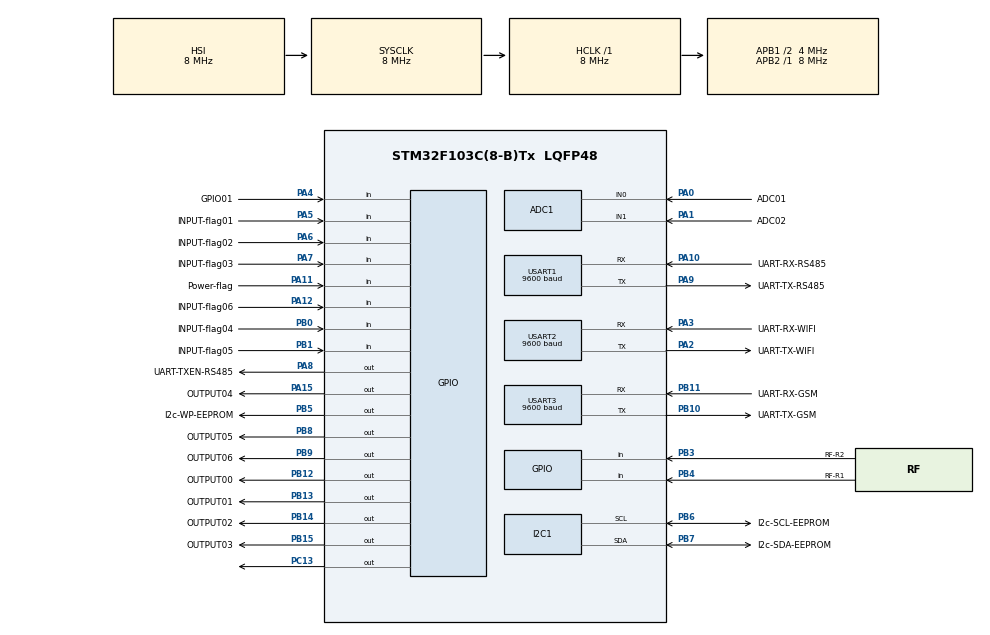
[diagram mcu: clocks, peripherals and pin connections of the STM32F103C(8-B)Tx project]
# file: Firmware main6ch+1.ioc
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ADC1.Channel-0\#ChannelRegularConversion=ADC_CHANNEL_0
ADC1.NbrOfConversionFlag=1
ADC1.Rank-0\#ChannelRegularConversion=1
ADC1.SamplingTime-0\#ChannelRegularConversion=ADC_SAMPLETIME_1CYCLE_5
ADC1.master=1
Mcu.Family=STM32F1
Mcu.Name=STM32F103C(8-B)Tx
Mcu.Package=LQFP48
NVIC.PriorityGroup=NVIC_PRIORITYGROUP_4
PA0-WKUP.GPIO_Label=ADC01
PA0-WKUP.Signal=ADCx_IN0
PA1.GPIO_Label=ADC02
PA1.Signal=ADCx_IN1
PA10.GPIO_Label=UART-RX-RS485
PA10.Mode=Asynchronous
PA10.Signal=USART1_RX
PA11.GPIO_Label=Power-flag
PA11.Signal=GPIO_Input
PA12.GPIO_Label=INPUT-flag06
PA12.Signal=GPIO_Input
PA13.Mode=Serial_Wire
PA13.Signal=SYS_JTMS-SWDIO
PA14.Mode=Serial_Wire
PA14.Signal=SYS_JTCK-SWCLK
PA15.GPIO_Label=OUTPUT04
PA15.Signal=GPIO_Output
PA2.GPIO_Label=UART-TX-WIFI
PA2.Mode=Asynchronous
PA2.Signal=USART2_TX
PA3.GPIO_Label=UART-RX-WIFI
PA3.Mode=Asynchronous
PA3.Signal=USART2_RX
PA4.GPIO_Label=GPIO01
PA4.Signal=GPIO_Input
PA5.GPIO_Label=INPUT-flag01
PA5.Signal=GPIO_Input
PA6.GPIO_Label=INPUT-flag02
PA6.Signal=GPIO_Input
PA7.GPIO_Label=INPUT-flag03
PA7.Signal=GPIO_Input
PA8.GPIO_Label=UART-TXEN-RS485
PA8.Signal=GPIO_Output
PA9.GPIO_Label=UART-TX-RS485
PA9.Mode=Asynchronous
PA9.Signal=USART1_TX
PB0.GPIO_Label=INPUT-flag04
PB0.Signal=GPIO_Input
PB1.GPIO_Label=INPUT-flag05
PB1.Signal=GPIO_Input
PB10.GPIO_Label=UART-TX-GSM
PB10.Mode=Asynchronous
PB10.Signal=USART3_TX
PB11.GPIO_Label=UART-RX-GSM
PB11.Mode=Asynchronous
PB11.Signal=USART3_RX
PB12.GPIO_Label=OUTPUT00
PB12.Signal=GPIO_Output
PB13.GPIO_Label=OUTPUT01
PB13.Signal=GPIO_Output
PB14.GPIO_Label=OUTPUT02
PB14.Signal=GPIO_Output
PB15.GPIO_Label=OUTPUT03
PB15.Signal=GPIO_Output
PB3.GPIO_Label=RF-R2
PB3.Signal=GPIO_Input
PB4.GPIO_Label=RF-R1
PB4.Signal=GPIO_Input
PB5.GPIO_Label=I2c-WP-EEPROM
PB5.Signal=GPIO_Output
PB6.GPIO_Label=I2c-SCL-EEPROM
PB6.Mode=I2C
PB6.Signal=I2C1_SCL
PB7.GPIO_Label=I2c-SDA-EEPROM
PB7.Mode=I2C
PB7.Signal=I2C1_SDA
PB8.GPIO_Label=OUTPUT05
PB8.Signal=GPIO_Output
PB9.GPIO_Label=OUTPUT06
PB9.Signal=GPIO_Output
PC13-TAMPER-RTC.Signal=GPIO_Output
ProjectManager.HeapSize=0x200
ProjectManager.StackSize=0x400
ProjectManager.TargetToolchain=STM32CubeIDE
RCC.ADCPresc=RCC_ADCPCLK2_DIV6
RCC.AHBFreq_Value=8000000
RCC.APB1CLKDivider=RCC_HCLK_DIV2
RCC.APB1Freq_Value=4000000
RCC.APB1TimFreq_Value=8000000
RCC.APB2Freq_Value=8000000
RCC.APB2TimFreq_Value=8000000
RCC.HCLKFreq_Value=8000000
RCC.PLLMUL=RCC_PLL_MUL8
RCC.SYSCLKFreq_VALUE=8000000
RCC.USBFreq_Value=21333333.333333332
RCC.USBPrescaler=RCC_USBCLKSOURCE_PLL_DIV1_5
SH.ADCx_IN0.0=ADC1_IN0,IN0
SH.ADCx_IN1.0=ADC1_IN1,IN1
USART1.BaudRate=9600
USART1.VirtualMode=VM_ASYNC
USART2.BaudRate=9600
USART2.VirtualMode=VM_ASYNC
USART3.BaudRate=9600
USART3.VirtualMode=VM_ASYNC
VP_RTC_VS_RTC_Activate.Mode=RTC_Enabled
VP_RTC_VS_RTC_Calendar.Mode=RTC_Calendar
board=custom

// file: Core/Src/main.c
/* USER CODE BEGIN Header */
/**
  ******************************************************************************
  * @file           : main.c
  * @brief          : Main program body
  ******************************************************************************
  * @attention
  *
  * Copyright (c) 2026 STMicroelectronics.
  * All rights reserved.
  *
  * This software is licensed under terms that can be found in the LICENSE file
  * in the root directory of this software component.
  * If no LICENSE file comes with this software, it is provided AS-IS.
  *
  ******************************************************************************
  */
/* USER CODE END Header */
#include "main.h"

ADC_HandleTypeDef hadc1;

I2C_HandleTypeDef hi2c1;

RTC_HandleTypeDef hrtc;

UART_HandleTypeDef huart1;
UART_HandleTypeDef huart2;
UART_HandleTypeDef huart3;

void SystemClock_Config(void);
static void MX_GPIO_Init(void);
static void MX_USART1_UART_Init(void);
static void MX_USART2_UART_Init(void);
static void MX_USART3_UART_Init(void);
static void MX_RTC_Init(void);
static void MX_I2C1_Init(void);
static void MX_ADC1_Init(void);

int main(void)
{

  /* MCU Configuration--------------------------------------------------------*/

  /* Reset of all peripherals, Initializes the Flash interface and the Systick. */
  HAL_Init();

  /* Configure the system clock */
  SystemClock_Config();

  /* Initialize all configured peripherals */
  MX_GPIO_Init();
  MX_USART1_UART_Init();
  MX_USART2_UART_Init();
  MX_USART3_UART_Init();
  MX_RTC_Init();
  MX_I2C1_Init();
  MX_ADC1_Init();
  /* USER CODE BEGIN 2 */
  #include "def.h"
  /* USER CODE END 2 */

  /* Infinite loop */
  /* USER CODE BEGIN WHILE */
  while (1)
  {
	  HAL_GPIO_WritePin(GPIOC, GPIO_PIN_13, GPIO_PIN_RESET);
	  HAL_Delay(1000);
	  HAL_GPIO_WritePin(GPIOC, GPIO_PIN_13, GPIO_PIN_SET);
	  HAL_Delay(1000);

    /* USER CODE END WHILE */

  }
}

void SystemClock_Config(void)
{
  RCC_OscInitTypeDef RCC_OscInitStruct = {0};
  RCC_ClkInitTypeDef RCC_ClkInitStruct = {0};
  RCC_PeriphCLKInitTypeDef PeriphClkInit = {0};

  /** Initializes the RCC Oscillators according to the specified parameters
  * in the RCC_OscInitTypeDef structure.
  */
  RCC_OscInitStruct.OscillatorType = RCC_OSCILLATORTYPE_HSI|RCC_OSCILLATORTYPE_LSI;
  RCC_OscInitStruct.HSIState = RCC_HSI_ON;
  RCC_OscInitStruct.HSICalibrationValue = RCC_HSICALIBRATION_DEFAULT;
  RCC_OscInitStruct.LSIState = RCC_LSI_ON;
  RCC_OscInitStruct.PLL.PLLState = RCC_PLL_NONE;
  if (HAL_RCC_OscConfig(&RCC_OscInitStruct) != HAL_OK)
  {
    Error_Handler();
  }

  /** Initializes the CPU, AHB and APB buses clocks
  */
  RCC_ClkInitStruct.ClockType = RCC_CLOCKTYPE_HCLK|RCC_CLOCKTYPE_SYSCLK
                              |RCC_CLOCKTYPE_PCLK1|RCC_CLOCKTYPE_PCLK2;
  RCC_ClkInitStruct.SYSCLKSource = RCC_SYSCLKSOURCE_HSI;
  RCC_ClkInitStruct.AHBCLKDivider = RCC_SYSCLK_DIV1;
  RCC_ClkInitStruct.APB1CLKDivider = RCC_HCLK_DIV2;
  RCC_ClkInitStruct.APB2CLKDivider = RCC_HCLK_DIV1;

  if (HAL_RCC_ClockConfig(&RCC_ClkInitStruct, FLASH_LATENCY_0) != HAL_OK)
  {
    Error_Handler();
  }
  PeriphClkInit.PeriphClockSelection = RCC_PERIPHCLK_RTC|RCC_PERIPHCLK_ADC;
  PeriphClkInit.RTCClockSelection = RCC_RTCCLKSOURCE_LSI;
  PeriphClkInit.AdcClockSelection = RCC_ADCPCLK2_DIV6;
  if (HAL_RCCEx_PeriphCLKConfig(&PeriphClkInit) != HAL_OK)
  {
    Error_Handler();
  }
}

static void MX_ADC1_Init(void)
{

  ADC_ChannelConfTypeDef sConfig = {0};

  /** Common config
  */
  hadc1.Instance = ADC1;
  hadc1.Init.ScanConvMode = ADC_SCAN_DISABLE;
  hadc1.Init.ContinuousConvMode = DISABLE;
  hadc1.Init.DiscontinuousConvMode = DISABLE;
  hadc1.Init.ExternalTrigConv = ADC_SOFTWARE_START;
  hadc1.Init.DataAlign = ADC_DATAALIGN_RIGHT;
  hadc1.Init.NbrOfConversion = 1;
  if (HAL_ADC_Init(&hadc1) != HAL_OK)
  {
    Error_Handler();
  }

  /** Configure Regular Channel
  */
  sConfig.Channel = ADC_CHANNEL_0;
  sConfig.Rank = ADC_REGULAR_RANK_1;
  sConfig.SamplingTime = ADC_SAMPLETIME_1CYCLE_5;
  if (HAL_ADC_ConfigChannel(&hadc1, &sConfig) != HAL_OK)
  {
    Error_Handler();
  }

}

static void MX_I2C1_Init(void)
{

  hi2c1.Instance = I2C1;
  hi2c1.Init.ClockSpeed = 100000;
  hi2c1.Init.DutyCycle = I2C_DUTYCYCLE_2;
  hi2c1.Init.OwnAddress1 = 0;
  hi2c1.Init.AddressingMode = I2C_ADDRESSINGMODE_7BIT;
  hi2c1.Init.DualAddressMode = I2C_DUALADDRESS_DISABLE;
  hi2c1.Init.OwnAddress2 = 0;
  hi2c1.Init.GeneralCallMode = I2C_GENERALCALL_DISABLE;
  hi2c1.Init.NoStretchMode = I2C_NOSTRETCH_DISABLE;
  if (HAL_I2C_Init(&hi2c1) != HAL_OK)
  {
    Error_Handler();
  }

}

static void MX_RTC_Init(void)
{

  RTC_TimeTypeDef sTime = {0};
  RTC_DateTypeDef DateToUpdate = {0};

  /** Initialize RTC Only
  */
  hrtc.Instance = RTC;
  hrtc.Init.AsynchPrediv = RTC_AUTO_1_SECOND;
  hrtc.Init.OutPut = RTC_OUTPUTSOURCE_ALARM;
  if (HAL_RTC_Init(&hrtc) != HAL_OK)
  {
    Error_Handler();
  }

  /** Initialize RTC and set the Time and Date
  */
  sTime.Hours = 0x0;
  sTime.Minutes = 0x0;
  sTime.Seconds = 0x0;

  if (HAL_RTC_SetTime(&hrtc, &sTime, RTC_FORMAT_BCD) != HAL_OK)
  {
    Error_Handler();
  }
  DateToUpdate.WeekDay = RTC_WEEKDAY_MONDAY;
  DateToUpdate.Month = RTC_MONTH_JANUARY;
  DateToUpdate.Date = 0x1;
  DateToUpdate.Year = 0x0;

  if (HAL_RTC_SetDate(&hrtc, &DateToUpdate, RTC_FORMAT_BCD) != HAL_OK)
  {
    Error_Handler();
  }

}

static void MX_USART1_UART_Init(void)
{

  huart1.Instance = USART1;
  huart1.Init.BaudRate = 9600;
  huart1.Init.WordLength = UART_WORDLENGTH_8B;
  huart1.Init.StopBits = UART_STOPBITS_1;
  huart1.Init.Parity = UART_PARITY_NONE;
  huart1.Init.Mode = UART_MODE_TX_RX;
  huart1.Init.HwFlowCtl = UART_HWCONTROL_NONE;
  huart1.Init.OverSampling = UART_OVERSAMPLING_16;
  if (HAL_UART_Init(&huart1) != HAL_OK)
  {
    Error_Handler();
  }

}

static void MX_USART2_UART_Init(void)
{

  huart2.Instance = USART2;
  huart2.Init.BaudRate = 9600;
  huart2.Init.WordLength = UART_WORDLENGTH_8B;
  huart2.Init.StopBits = UART_STOPBITS_1;
  huart2.Init.Parity = UART_PARITY_NONE;
  huart2.Init.Mode = UART_MODE_TX_RX;
  huart2.Init.HwFlowCtl = UART_HWCONTROL_NONE;
  huart2.Init.OverSampling = UART_OVERSAMPLING_16;
  if (HAL_UART_Init(&huart2) != HAL_OK)
  {
    Error_Handler();
  }

}

static void MX_USART3_UART_Init(void)
{

  huart3.Instance = USART3;
  huart3.Init.BaudRate = 9600;
  huart3.Init.WordLength = UART_WORDLENGTH_8B;
  huart3.Init.StopBits = UART_STOPBITS_1;
  huart3.Init.Parity = UART_PARITY_NONE;
  huart3.Init.Mode = UART_MODE_TX_RX;
  huart3.Init.HwFlowCtl = UART_HWCONTROL_NONE;
  huart3.Init.OverSampling = UART_OVERSAMPLING_16;
  if (HAL_UART_Init(&huart3) != HAL_OK)
  {
    Error_Handler();
  }

}

static void MX_GPIO_Init(void)
{
  GPIO_InitTypeDef GPIO_InitStruct = {0};

  /* GPIO Ports Clock Enable */
  __HAL_RCC_GPIOC_CLK_ENABLE();
  __HAL_RCC_GPIOA_CLK_ENABLE();
  __HAL_RCC_GPIOB_CLK_ENABLE();

  /*Configure GPIO pin Output Level */
  HAL_GPIO_WritePin(GPIOC, GPIO_PIN_13, GPIO_PIN_RESET);

  /*Configure GPIO pin Output Level */
  HAL_GPIO_WritePin(GPIOB, OUTPUT00_Pin|OUTPUT01_Pin|OUTPUT02_Pin|OUTPUT03_Pin
                          |I2c_WP_EEPROM_Pin|OUTPUT05_Pin|OUTPUT06_Pin, GPIO_PIN_RESET);

  /*Configure GPIO pin Output Level */
  HAL_GPIO_WritePin(GPIOA, UART_TXEN_RS485_Pin|OUTPUT04_Pin, GPIO_PIN_RESET);

  /*Configure GPIO pin : PC13 */
  GPIO_InitStruct.Pin = GPIO_PIN_13;
  GPIO_InitStruct.Mode = GPIO_MODE_OUTPUT_PP;
  GPIO_InitStruct.Pull = GPIO_NOPULL;
  GPIO_InitStruct.Speed = GPIO_SPEED_FREQ_LOW;
  HAL_GPIO_Init(GPIOC, &GPIO_InitStruct);

  /*Configure GPIO pins : GPIO01_Pin INPUT_flag01_Pin INPUT_flag02_Pin INPUT_flag03_Pin
                           Power_flag_Pin INPUT_flag06_Pin */
  GPIO_InitStruct.Pin = GPIO01_Pin|INPUT_flag01_Pin|INPUT_flag02_Pin|INPUT_flag03_Pin
                          |Power_flag_Pin|INPUT_flag06_Pin;
  GPIO_InitStruct.Mode = GPIO_MODE_INPUT;
  GPIO_InitStruct.Pull = GPIO_NOPULL;
  HAL_GPIO_Init(GPIOA, &GPIO_InitStruct);

  /*Configure GPIO pins : INPUT_flag04_Pin INPUT_flag05_Pin RF_R2_Pin RF_R1_Pin */
  GPIO_InitStruct.Pin = INPUT_flag04_Pin|INPUT_flag05_Pin|RF_R2_Pin|RF_R1_Pin;
  GPIO_InitStruct.Mode = GPIO_MODE_INPUT;
  GPIO_InitStruct.Pull = GPIO_NOPULL;
  HAL_GPIO_Init(GPIOB, &GPIO_InitStruct);

  /*Configure GPIO pins : OUTPUT00_Pin OUTPUT01_Pin OUTPUT02_Pin OUTPUT03_Pin
                           I2c_WP_EEPROM_Pin OUTPUT05_Pin OUTPUT06_Pin */
  GPIO_InitStruct.Pin = OUTPUT00_Pin|OUTPUT01_Pin|OUTPUT02_Pin|OUTPUT03_Pin
                          |I2c_WP_EEPROM_Pin|OUTPUT05_Pin|OUTPUT06_Pin;
  GPIO_InitStruct.Mode = GPIO_MODE_OUTPUT_PP;
  GPIO_InitStruct.Pull = GPIO_NOPULL;
  GPIO_InitStruct.Speed = GPIO_SPEED_FREQ_LOW;
  HAL_GPIO_Init(GPIOB, &GPIO_InitStruct);

  /*Configure GPIO pins : UART_TXEN_RS485_Pin OUTPUT04_Pin */
  GPIO_InitStruct.Pin = UART_TXEN_RS485_Pin|OUTPUT04_Pin;
  GPIO_InitStruct.Mode = GPIO_MODE_OUTPUT_PP;
  GPIO_InitStruct.Pull = GPIO_NOPULL;
  GPIO_InitStruct.Speed = GPIO_SPEED_FREQ_LOW;
  HAL_GPIO_Init(GPIOA, &GPIO_InitStruct);

}

void Error_Handler(void)
{
  __disable_irq();
  while (1)
  {
  }
}
